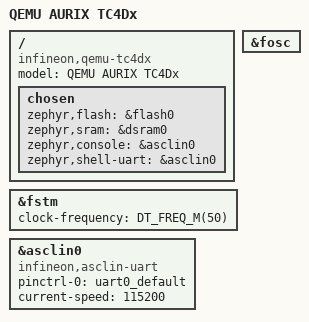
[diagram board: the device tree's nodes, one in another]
/* SPDX-License-Identifier: Apache-2.0 */

/dts-v1/;

#include <infineon/tc4x/tc4d7xp.dtsi>
#include "qemu_tc4x-pinctrl.dtsi"

/ {
	model = "QEMU AURIX TC4Dx";
	compatible = "infineon,qemu-tc4dx";
	chosen {
		zephyr,flash = &flash0;
		zephyr,sram = &dsram0;
		zephyr,console = &asclin0;
		zephyr,shell-uart = &asclin0;
	};
};

&fosc {
	status = "okay";
};

&fstm {
	clock-frequency = <DT_FREQ_M(50)>;
};

&asclin0 {
	compatible = "infineon,asclin-uart";
	pinctrl-0 = <&uart0_default>;
	pinctrl-names = "default";
	current-speed = <115200>;
	status = "okay";
};
